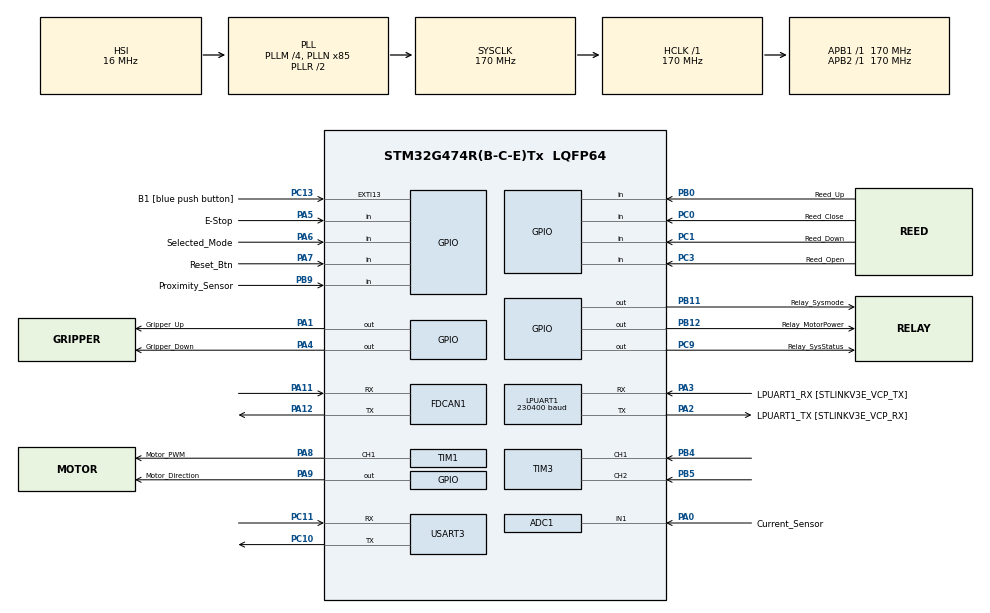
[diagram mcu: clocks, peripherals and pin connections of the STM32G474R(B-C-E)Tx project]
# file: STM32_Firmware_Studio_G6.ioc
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ADC1.Channel-0\#ChannelRegularConversion=ADC_CHANNEL_1
ADC1.ContinuousConvMode=ENABLE
ADC1.DMAContinuousRequests=ENABLE
ADC1.NbrOfConversionFlag=1
ADC1.OffsetNumber-0\#ChannelRegularConversion=ADC_OFFSET_NONE
ADC1.Rank-0\#ChannelRegularConversion=1
ADC1.SamplingTime-0\#ChannelRegularConversion=ADC_SAMPLETIME_2CYCLES_5
ADC1.master=1
Dma.ADC1.0.Direction=DMA_PERIPH_TO_MEMORY
Dma.ADC1.0.EventEnable=DISABLE
Dma.ADC1.0.Instance=DMA1_Channel1
Dma.ADC1.0.MemDataAlignment=DMA_MDATAALIGN_HALFWORD
Dma.ADC1.0.MemInc=DMA_MINC_ENABLE
Dma.ADC1.0.Mode=DMA_CIRCULAR
Dma.ADC1.0.PeriphDataAlignment=DMA_PDATAALIGN_HALFWORD
Dma.ADC1.0.PeriphInc=DMA_PINC_DISABLE
Dma.ADC1.0.Polarity=HAL_DMAMUX_REQ_GEN_RISING
Dma.ADC1.0.Priority=DMA_PRIORITY_LOW
Dma.ADC1.0.RequestNumber=1
Dma.ADC1.0.SignalID=NONE
Dma.ADC1.0.SyncEnable=DISABLE
Dma.ADC1.0.SyncPolarity=HAL_DMAMUX_SYNC_NO_EVENT
Dma.ADC1.0.SyncRequestNumber=1
Dma.ADC1.0.SyncSignalID=NONE
Dma.LPUART1_RX.1.Direction=DMA_PERIPH_TO_MEMORY
Dma.LPUART1_RX.1.EventEnable=DISABLE
Dma.LPUART1_RX.1.Instance=DMA1_Channel2
Dma.LPUART1_RX.1.MemDataAlignment=DMA_MDATAALIGN_BYTE
Dma.LPUART1_RX.1.MemInc=DMA_MINC_ENABLE
Dma.LPUART1_RX.1.Mode=DMA_NORMAL
Dma.LPUART1_RX.1.PeriphDataAlignment=DMA_PDATAALIGN_BYTE
Dma.LPUART1_RX.1.PeriphInc=DMA_PINC_DISABLE
Dma.LPUART1_RX.1.Polarity=HAL_DMAMUX_REQ_GEN_RISING
Dma.LPUART1_RX.1.Priority=DMA_PRIORITY_LOW
Dma.LPUART1_RX.1.RequestNumber=1
Dma.LPUART1_RX.1.SignalID=NONE
Dma.LPUART1_RX.1.SyncEnable=DISABLE
Dma.LPUART1_RX.1.SyncPolarity=HAL_DMAMUX_SYNC_NO_EVENT
Dma.LPUART1_RX.1.SyncRequestNumber=1
Dma.LPUART1_RX.1.SyncSignalID=NONE
Dma.LPUART1_TX.2.Direction=DMA_MEMORY_TO_PERIPH
Dma.LPUART1_TX.2.EventEnable=DISABLE
Dma.LPUART1_TX.2.Instance=DMA1_Channel3
Dma.LPUART1_TX.2.MemDataAlignment=DMA_MDATAALIGN_BYTE
Dma.LPUART1_TX.2.MemInc=DMA_MINC_ENABLE
Dma.LPUART1_TX.2.Mode=DMA_NORMAL
Dma.LPUART1_TX.2.PeriphDataAlignment=DMA_PDATAALIGN_BYTE
Dma.LPUART1_TX.2.PeriphInc=DMA_PINC_DISABLE
Dma.LPUART1_TX.2.Polarity=HAL_DMAMUX_REQ_GEN_RISING
Dma.LPUART1_TX.2.Priority=DMA_PRIORITY_LOW
Dma.LPUART1_TX.2.RequestNumber=1
Dma.LPUART1_TX.2.SignalID=NONE
Dma.LPUART1_TX.2.SyncEnable=DISABLE
Dma.LPUART1_TX.2.SyncPolarity=HAL_DMAMUX_SYNC_NO_EVENT
Dma.LPUART1_TX.2.SyncRequestNumber=1
Dma.LPUART1_TX.2.SyncSignalID=NONE
Dma.Request0=ADC1
Dma.Request1=LPUART1_RX
Dma.Request2=LPUART1_TX
Dma.Request3=USART3_RX
Dma.Request4=USART3_TX
Dma.USART3_RX.3.Direction=DMA_PERIPH_TO_MEMORY
Dma.USART3_RX.3.EventEnable=DISABLE
Dma.USART3_RX.3.Instance=DMA1_Channel4
Dma.USART3_RX.3.MemDataAlignment=DMA_MDATAALIGN_BYTE
Dma.USART3_RX.3.MemInc=DMA_MINC_ENABLE
Dma.USART3_RX.3.Mode=DMA_NORMAL
Dma.USART3_RX.3.PeriphDataAlignment=DMA_PDATAALIGN_BYTE
Dma.USART3_RX.3.PeriphInc=DMA_PINC_DISABLE
Dma.USART3_RX.3.Polarity=HAL_DMAMUX_REQ_GEN_RISING
Dma.USART3_RX.3.Priority=DMA_PRIORITY_LOW
Dma.USART3_RX.3.RequestNumber=1
Dma.USART3_RX.3.SignalID=NONE
Dma.USART3_RX.3.SyncEnable=DISABLE
Dma.USART3_RX.3.SyncPolarity=HAL_DMAMUX_SYNC_NO_EVENT
Dma.USART3_RX.3.SyncRequestNumber=1
Dma.USART3_RX.3.SyncSignalID=NONE
Dma.USART3_TX.4.Direction=DMA_MEMORY_TO_PERIPH
Dma.USART3_TX.4.EventEnable=DISABLE
Dma.USART3_TX.4.Instance=DMA1_Channel5
Dma.USART3_TX.4.MemDataAlignment=DMA_MDATAALIGN_BYTE
Dma.USART3_TX.4.MemInc=DMA_MINC_ENABLE
Dma.USART3_TX.4.Mode=DMA_NORMAL
Dma.USART3_TX.4.PeriphDataAlignment=DMA_PDATAALIGN_BYTE
Dma.USART3_TX.4.PeriphInc=DMA_PINC_DISABLE
Dma.USART3_TX.4.Polarity=HAL_DMAMUX_REQ_GEN_RISING
Dma.USART3_TX.4.Priority=DMA_PRIORITY_LOW
Dma.USART3_TX.4.RequestNumber=1
Dma.USART3_TX.4.SignalID=NONE
Dma.USART3_TX.4.SyncEnable=DISABLE
Dma.USART3_TX.4.SyncPolarity=HAL_DMAMUX_SYNC_NO_EVENT
Dma.USART3_TX.4.SyncRequestNumber=1
Dma.USART3_TX.4.SyncSignalID=NONE
FDCAN1.CalculateBaudRateNominal=3541666
FDCAN1.CalculateTimeBitNominal=282
FDCAN1.CalculateTimeQuantumNominal=94.11764705882354
LPUART1.BaudRate=230400
LPUART1.Parity=UART_PARITY_EVEN
LPUART1.WordLength=UART_WORDLENGTH_9B
Mcu.Family=STM32G4
Mcu.Name=STM32G474R(B-C-E)Tx
Mcu.Package=LQFP64
NVIC.DMA1_Channel1_IRQn=true\:4\:0\:true\:false\:true\:false\:true\:true
NVIC.DMA1_Channel2_IRQn=true\:4\:0\:true\:false\:true\:false\:true\:true
NVIC.DMA1_Channel3_IRQn=true\:4\:0\:true\:false\:true\:false\:true\:true
NVIC.DMA1_Channel4_IRQn=true\:4\:0\:true\:false\:true\:false\:true\:true
NVIC.DMA1_Channel5_IRQn=true\:4\:0\:true\:false\:true\:false\:true\:true
NVIC.EXTI15_10_IRQn=true\:0\:0\:false\:false\:true\:true\:true\:true
NVIC.LPUART1_IRQn=true\:4\:0\:true\:false\:true\:true\:true\:true
NVIC.PriorityGroup=NVIC_PRIORITYGROUP_4
NVIC.TIM6_DAC_IRQn=true\:1\:0\:true\:false\:true\:true\:true\:true
NVIC.USART3_IRQn=true\:3\:0\:true\:false\:true\:true\:true\:true
PA0.GPIO_Label=Current_Sensor
PA0.Mode=IN1-Single-Ended
PA0.Signal=ADC1_IN1
PA1.GPIO_Label=Gripper_Up
PA1.Signal=GPIO_Output
PA11.Mode=FDCAN_Activate
PA11.Signal=FDCAN1_RX
PA12.Mode=FDCAN_Activate
PA12.Signal=FDCAN1_TX
PA13.GPIO_Label=T_SWDIO
PA13.Signal=SYS_JTMS-SWDIO
PA14.GPIO_Label=T_SWCLK
PA14.Signal=SYS_JTCK-SWCLK
PA2.GPIO_Label=LPUART1_TX [STLINKV3E_VCP_RX]
PA2.Mode=Asynchronous
PA2.Signal=LPUART1_TX
PA3.GPIO_Label=LPUART1_RX [STLINKV3E_VCP_TX]
PA3.Mode=Asynchronous
PA3.Signal=LPUART1_RX
PA4.GPIO_Label=Gripper_Down
PA4.Signal=GPIO_Output
PA5.GPIO_Label=E-Stop
PA5.GPIO_PuPd=GPIO_PULLUP
PA5.Signal=GPIO_Input
PA6.GPIO_Label=Selected_Mode
PA6.GPIO_PuPd=GPIO_PULLUP
PA6.Signal=GPIO_Input
PA7.GPIO_Label=Reset_Btn
PA7.GPIO_PuPd=GPIO_PULLUP
PA7.Signal=GPIO_Input
PA8.GPIO_Label=Motor_PWM
PA8.Signal=S_TIM1_CH1
PA9.GPIO_Label=Motor_Direction
PA9.Signal=GPIO_Output
PB0.GPIO_Label=Reed_Up
PB0.GPIO_PuPd=GPIO_PULLDOWN
PB0.Signal=GPIO_Input
PB11.GPIO_Label=Relay_Sysmode
PB11.Signal=GPIO_Output
PB12.GPIO_Label=Relay_MotorPower
PB12.Signal=GPIO_Output
PB3.GPIO_Label=T_SWO
PB3.Signal=SYS_JTDO-SWO
PB4.GPIO_PuPd=GPIO_NOPULL
PB4.Signal=S_TIM3_CH1
PB5.GPIO_PuPd=GPIO_NOPULL
PB5.Signal=S_TIM3_CH2
PB9.GPIO_Label=Proximity_Sensor
PB9.GPIO_PuPd=GPIO_PULLUP
PB9.Signal=GPIO_Input
PC0.GPIO_Label=Reed_Close
PC0.GPIO_PuPd=GPIO_PULLDOWN
PC0.Signal=GPIO_Input
PC1.GPIO_Label=Reed_Down
PC1.GPIO_PuPd=GPIO_PULLDOWN
PC1.Signal=GPIO_Input
PC10.Mode=Asynchronous
PC10.Signal=USART3_TX
PC11.Mode=Asynchronous
PC11.Signal=USART3_RX
PC13.GPIO_Label=B1 [blue push button]
PC13.Signal=GPXTI13
PC14-OSC32_IN.GPIO_Label=RCC_OSC32_IN
PC14-OSC32_IN.Signal=RCC_OSC32_IN
PC15-OSC32_OUT.GPIO_Label=RCC_OSC32_OUT
PC15-OSC32_OUT.Signal=RCC_OSC32_OUT
PC3.GPIO_Label=Reed_Open
PC3.GPIO_PuPd=GPIO_PULLDOWN
PC3.Signal=GPIO_Input
PC9.GPIO_Label=Relay_SysStatus
PC9.Signal=GPIO_Output
PF0-OSC_IN.GPIO_Label=RCC_OSC_IN
PF0-OSC_IN.Signal=RCC_OSC_IN
PF1-OSC_OUT.GPIO_Label=RCC_OSC_OUT
PF1-OSC_OUT.Signal=RCC_OSC_OUT
ProjectManager.HeapSize=0x200
ProjectManager.StackSize=0x400
ProjectManager.TargetToolchain=STM32CubeIDE
RCC.ADC12Freq_Value=170000000
RCC.ADC345Freq_Value=170000000
RCC.AHBFreq_Value=170000000
RCC.APB1Freq_Value=170000000
RCC.APB1TimFreq_Value=170000000
RCC.APB2Freq_Value=170000000
RCC.APB2TimFreq_Value=170000000
RCC.CortexFreq_Value=170000000
RCC.EXTERNAL_CLOCK_VALUE=12288000
RCC.HCLKFreq_Value=170000000
RCC.HSE_VALUE=24000000
RCC.HSI48_VALUE=48000000
RCC.HSI_VALUE=16000000
RCC.LSE_VALUE=32768
RCC.PLLM=RCC_PLLM_DIV4
RCC.PLLN=85
RCC.RTCClockSelection=RCC_RTCCLKSOURCE_LSE
RCC.SYSCLKFreq_VALUE=170000000
RCC.SYSCLKSource=RCC_SYSCLKSOURCE_PLLCLK
RCC.USBFreq_Value=170000000
RCC.VCOOutputFreq_Value=340000000
SH.S_TIM1_CH1.0=TIM1_CH1,PWM Generation1 CH1
SH.S_TIM3_CH1.0=TIM3_CH1,Encoder_Interface
SH.S_TIM3_CH2.0=TIM3_CH2,Encoder_Interface
TIM1.Channel-PWM\ Generation1\ CH1=TIM_CHANNEL_1
TIM1.PeriodNoDither=50
TIM1.Prescaler=169
TIM3.EncoderMode=TIM_ENCODERMODE_TI12
TIM6.PeriodNoDither=999
TIM6.Prescaler=169
USART3.SwapParam=ADVFEATURE_SWAP_ENABLE
USART3.VirtualMode-Asynchronous=VM_ASYNC
VP_SYS_VS_DBSignals.Mode=DisableDeadBatterySignals
VP_TIM6_VS_ClockSourceINT.Mode=Enable_Timer
board=NUCLEO-G474RE

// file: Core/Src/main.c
/* USER CODE BEGIN Header */
/**
  ******************************************************************************
  * @file           : main.c
  * @brief          : Main program body
  ******************************************************************************
  * @attention
  *
  * Copyright (c) 2026 STMicroelectronics.
  * All rights reserved.
  *
  * This software is licensed under terms that can be found in the LICENSE file
  * in the root directory of this software component.
  * If no LICENSE file comes with this software, it is provided AS-IS.
  *
  ******************************************************************************
  */
/* USER CODE END Header */
#include "main.h"

/* USER CODE BEGIN Includes */
#include "app_main.h"
/* USER CODE END Includes */

ADC_HandleTypeDef hadc1;
DMA_HandleTypeDef hdma_adc1;

FDCAN_HandleTypeDef hfdcan1;

UART_HandleTypeDef hlpuart1;
UART_HandleTypeDef huart3;
DMA_HandleTypeDef hdma_lpuart1_rx;
DMA_HandleTypeDef hdma_lpuart1_tx;
DMA_HandleTypeDef hdma_usart3_rx;
DMA_HandleTypeDef hdma_usart3_tx;

TIM_HandleTypeDef htim1;
TIM_HandleTypeDef htim3;
TIM_HandleTypeDef htim6;

void SystemClock_Config(void);
static void MX_GPIO_Init(void);
static void MX_DMA_Init(void);
static void MX_ADC1_Init(void);
static void MX_LPUART1_UART_Init(void);
static void MX_TIM1_Init(void);
static void MX_TIM3_Init(void);
static void MX_TIM6_Init(void);
static void MX_USART3_UART_Init(void);
static void MX_FDCAN1_Init(void);

int main(void)
{

  /* MCU Configuration--------------------------------------------------------*/

  /* Reset of all peripherals, Initializes the Flash interface and the Systick. */
  HAL_Init();

  /* Configure the system clock */
  SystemClock_Config();

  /* Initialize all configured peripherals */

  MX_GPIO_Init();
  MX_DMA_Init();
  MX_ADC1_Init();
  MX_LPUART1_UART_Init();
  MX_TIM1_Init();
  MX_TIM3_Init();
  MX_TIM6_Init();
  MX_USART3_UART_Init();
  MX_FDCAN1_Init();
  /* USER CODE BEGIN 2 */
  App_Init();
  /* USER CODE END 2 */

  /* Infinite loop */
  while (1)
  {

    /* USER CODE BEGIN 3 */

    App_Run();
  }
  /* USER CODE END 3 */
}

void SystemClock_Config(void)
{
  RCC_OscInitTypeDef RCC_OscInitStruct = {0};
  RCC_ClkInitTypeDef RCC_ClkInitStruct = {0};

  /** Configure the main internal regulator output voltage
  */
  HAL_PWREx_ControlVoltageScaling(PWR_REGULATOR_VOLTAGE_SCALE1_BOOST);

  /** Initializes the RCC Oscillators according to the specified parameters
  * in the RCC_OscInitTypeDef structure.
  */
  RCC_OscInitStruct.OscillatorType = RCC_OSCILLATORTYPE_HSI;
  RCC_OscInitStruct.HSIState = RCC_HSI_ON;
  RCC_OscInitStruct.HSICalibrationValue = RCC_HSICALIBRATION_DEFAULT;
  RCC_OscInitStruct.PLL.PLLState = RCC_PLL_ON;
  RCC_OscInitStruct.PLL.PLLSource = RCC_PLLSOURCE_HSI;
  RCC_OscInitStruct.PLL.PLLM = RCC_PLLM_DIV4;
  RCC_OscInitStruct.PLL.PLLN = 85;
  RCC_OscInitStruct.PLL.PLLP = RCC_PLLP_DIV2;
  RCC_OscInitStruct.PLL.PLLQ = RCC_PLLQ_DIV2;
  RCC_OscInitStruct.PLL.PLLR = RCC_PLLR_DIV2;
  if (HAL_RCC_OscConfig(&RCC_OscInitStruct) != HAL_OK)
  {
    Error_Handler();
  }

  /** Initializes the CPU, AHB and APB buses clocks
  */
  RCC_ClkInitStruct.ClockType = RCC_CLOCKTYPE_HCLK|RCC_CLOCKTYPE_SYSCLK
                              |RCC_CLOCKTYPE_PCLK1|RCC_CLOCKTYPE_PCLK2;
  RCC_ClkInitStruct.SYSCLKSource = RCC_SYSCLKSOURCE_PLLCLK;
  RCC_ClkInitStruct.AHBCLKDivider = RCC_SYSCLK_DIV1;
  RCC_ClkInitStruct.APB1CLKDivider = RCC_HCLK_DIV1;
  RCC_ClkInitStruct.APB2CLKDivider = RCC_HCLK_DIV1;

  if (HAL_RCC_ClockConfig(&RCC_ClkInitStruct, FLASH_LATENCY_4) != HAL_OK)
  {
    Error_Handler();
  }
}

static void MX_ADC1_Init(void)
{

  ADC_MultiModeTypeDef multimode = {0};
  ADC_ChannelConfTypeDef sConfig = {0};

  /** Common config
  */
  hadc1.Instance = ADC1;
  hadc1.Init.ClockPrescaler = ADC_CLOCK_SYNC_PCLK_DIV4;
  hadc1.Init.Resolution = ADC_RESOLUTION_12B;
  hadc1.Init.DataAlign = ADC_DATAALIGN_RIGHT;
  hadc1.Init.GainCompensation = 0;
  hadc1.Init.ScanConvMode = ADC_SCAN_DISABLE;
  hadc1.Init.EOCSelection = ADC_EOC_SINGLE_CONV;
  hadc1.Init.LowPowerAutoWait = DISABLE;
  hadc1.Init.ContinuousConvMode = ENABLE;
  hadc1.Init.NbrOfConversion = 1;
  hadc1.Init.DiscontinuousConvMode = DISABLE;
  hadc1.Init.ExternalTrigConv = ADC_SOFTWARE_START;
  hadc1.Init.ExternalTrigConvEdge = ADC_EXTERNALTRIGCONVEDGE_NONE;
  hadc1.Init.DMAContinuousRequests = ENABLE;
  hadc1.Init.Overrun = ADC_OVR_DATA_PRESERVED;
  hadc1.Init.OversamplingMode = DISABLE;
  if (HAL_ADC_Init(&hadc1) != HAL_OK)
  {
    Error_Handler();
  }

  /** Configure the ADC multi-mode
  */
  multimode.Mode = ADC_MODE_INDEPENDENT;
  if (HAL_ADCEx_MultiModeConfigChannel(&hadc1, &multimode) != HAL_OK)
  {
    Error_Handler();
  }

  /** Configure Regular Channel
  */
  sConfig.Channel = ADC_CHANNEL_1;
  sConfig.Rank = ADC_REGULAR_RANK_1;
  sConfig.SamplingTime = ADC_SAMPLETIME_2CYCLES_5;
  sConfig.SingleDiff = ADC_SINGLE_ENDED;
  sConfig.OffsetNumber = ADC_OFFSET_NONE;
  sConfig.Offset = 0;
  if (HAL_ADC_ConfigChannel(&hadc1, &sConfig) != HAL_OK)
  {
    Error_Handler();
  }

}

static void MX_FDCAN1_Init(void)
{

  hfdcan1.Instance = FDCAN1;
  hfdcan1.Init.ClockDivider = FDCAN_CLOCK_DIV1;
  hfdcan1.Init.FrameFormat = FDCAN_FRAME_CLASSIC;
  hfdcan1.Init.Mode = FDCAN_MODE_NORMAL;
  hfdcan1.Init.AutoRetransmission = DISABLE;
  hfdcan1.Init.TransmitPause = DISABLE;
  hfdcan1.Init.ProtocolException = DISABLE;
  hfdcan1.Init.NominalPrescaler = 16;
  hfdcan1.Init.NominalSyncJumpWidth = 1;
  hfdcan1.Init.NominalTimeSeg1 = 1;
  hfdcan1.Init.NominalTimeSeg2 = 1;
  hfdcan1.Init.DataPrescaler = 1;
  hfdcan1.Init.DataSyncJumpWidth = 1;
  hfdcan1.Init.DataTimeSeg1 = 1;
  hfdcan1.Init.DataTimeSeg2 = 1;
  hfdcan1.Init.StdFiltersNbr = 0;
  hfdcan1.Init.ExtFiltersNbr = 0;
  hfdcan1.Init.TxFifoQueueMode = FDCAN_TX_FIFO_OPERATION;
  if (HAL_FDCAN_Init(&hfdcan1) != HAL_OK)
  {
    Error_Handler();
  }

}

static void MX_LPUART1_UART_Init(void)
{

  hlpuart1.Instance = LPUART1;
  hlpuart1.Init.BaudRate = 230400;
  hlpuart1.Init.WordLength = UART_WORDLENGTH_9B;
  hlpuart1.Init.StopBits = UART_STOPBITS_1;
  hlpuart1.Init.Parity = UART_PARITY_EVEN;
  hlpuart1.Init.Mode = UART_MODE_TX_RX;
  hlpuart1.Init.HwFlowCtl = UART_HWCONTROL_NONE;
  hlpuart1.Init.OneBitSampling = UART_ONE_BIT_SAMPLE_DISABLE;
  hlpuart1.Init.ClockPrescaler = UART_PRESCALER_DIV1;
  hlpuart1.AdvancedInit.AdvFeatureInit = UART_ADVFEATURE_NO_INIT;
  if (HAL_UART_Init(&hlpuart1) != HAL_OK)
  {
    Error_Handler();
  }
  if (HAL_UARTEx_SetTxFifoThreshold(&hlpuart1, UART_TXFIFO_THRESHOLD_1_8) != HAL_OK)
  {
    Error_Handler();
  }
  if (HAL_UARTEx_SetRxFifoThreshold(&hlpuart1, UART_RXFIFO_THRESHOLD_1_8) != HAL_OK)
  {
    Error_Handler();
  }
  if (HAL_UARTEx_DisableFifoMode(&hlpuart1) != HAL_OK)
  {
    Error_Handler();
  }

}

static void MX_USART3_UART_Init(void)
{

  huart3.Instance = USART3;
  huart3.Init.BaudRate = 115200;
  huart3.Init.WordLength = UART_WORDLENGTH_8B;
  huart3.Init.StopBits = UART_STOPBITS_1;
  huart3.Init.Parity = UART_PARITY_NONE;
  huart3.Init.Mode = UART_MODE_TX_RX;
  huart3.Init.HwFlowCtl = UART_HWCONTROL_NONE;
  huart3.Init.OverSampling = UART_OVERSAMPLING_16;
  huart3.Init.OneBitSampling = UART_ONE_BIT_SAMPLE_DISABLE;
  huart3.Init.ClockPrescaler = UART_PRESCALER_DIV1;
  huart3.AdvancedInit.AdvFeatureInit = UART_ADVFEATURE_SWAP_INIT;
  huart3.AdvancedInit.Swap = UART_ADVFEATURE_SWAP_ENABLE;
  if (HAL_UART_Init(&huart3) != HAL_OK)
  {
    Error_Handler();
  }
  if (HAL_UARTEx_SetTxFifoThreshold(&huart3, UART_TXFIFO_THRESHOLD_1_8) != HAL_OK)
  {
    Error_Handler();
  }
  if (HAL_UARTEx_SetRxFifoThreshold(&huart3, UART_RXFIFO_THRESHOLD_1_8) != HAL_OK)
  {
    Error_Handler();
  }
  if (HAL_UARTEx_DisableFifoMode(&huart3) != HAL_OK)
  {
    Error_Handler();
  }

}

static void MX_TIM1_Init(void)
{

  TIM_MasterConfigTypeDef sMasterConfig = {0};
  TIM_OC_InitTypeDef sConfigOC = {0};
  TIM_BreakDeadTimeConfigTypeDef sBreakDeadTimeConfig = {0};

  htim1.Instance = TIM1;
  htim1.Init.Prescaler = 169;
  htim1.Init.CounterMode = TIM_COUNTERMODE_UP;
  htim1.Init.Period = 50;
  htim1.Init.ClockDivision = TIM_CLOCKDIVISION_DIV1;
  htim1.Init.RepetitionCounter = 0;
  htim1.Init.AutoReloadPreload = TIM_AUTORELOAD_PRELOAD_DISABLE;
  if (HAL_TIM_PWM_Init(&htim1) != HAL_OK)
  {
    Error_Handler();
  }
  sMasterConfig.MasterOutputTrigger = TIM_TRGO_RESET;
  sMasterConfig.MasterOutputTrigger2 = TIM_TRGO2_RESET;
  sMasterConfig.MasterSlaveMode = TIM_MASTERSLAVEMODE_DISABLE;
  if (HAL_TIMEx_MasterConfigSynchronization(&htim1, &sMasterConfig) != HAL_OK)
  {
    Error_Handler();
  }
  sConfigOC.OCMode = TIM_OCMODE_PWM1;
  sConfigOC.Pulse = 0;
  sConfigOC.OCPolarity = TIM_OCPOLARITY_HIGH;
  sConfigOC.OCNPolarity = TIM_OCNPOLARITY_HIGH;
  sConfigOC.OCFastMode = TIM_OCFAST_DISABLE;
  sConfigOC.OCIdleState = TIM_OCIDLESTATE_RESET;
  sConfigOC.OCNIdleState = TIM_OCNIDLESTATE_RESET;
  if (HAL_TIM_PWM_ConfigChannel(&htim1, &sConfigOC, TIM_CHANNEL_1) != HAL_OK)
  {
    Error_Handler();
  }
  sBreakDeadTimeConfig.OffStateRunMode = TIM_OSSR_DISABLE;
  sBreakDeadTimeConfig.OffStateIDLEMode = TIM_OSSI_DISABLE;
  sBreakDeadTimeConfig.LockLevel = TIM_LOCKLEVEL_OFF;
  sBreakDeadTimeConfig.DeadTime = 0;
  sBreakDeadTimeConfig.BreakState = TIM_BREAK_DISABLE;
  sBreakDeadTimeConfig.BreakPolarity = TIM_BREAKPOLARITY_HIGH;
  sBreakDeadTimeConfig.BreakFilter = 0;
  sBreakDeadTimeConfig.BreakAFMode = TIM_BREAK_AFMODE_INPUT;
  sBreakDeadTimeConfig.Break2State = TIM_BREAK2_DISABLE;
  sBreakDeadTimeConfig.Break2Polarity = TIM_BREAK2POLARITY_HIGH;
  sBreakDeadTimeConfig.Break2Filter = 0;
  sBreakDeadTimeConfig.Break2AFMode = TIM_BREAK_AFMODE_INPUT;
  sBreakDeadTimeConfig.AutomaticOutput = TIM_AUTOMATICOUTPUT_DISABLE;
  if (HAL_TIMEx_ConfigBreakDeadTime(&htim1, &sBreakDeadTimeConfig) != HAL_OK)
  {
    Error_Handler();
  }
  HAL_TIM_MspPostInit(&htim1);

}

static void MX_TIM3_Init(void)
{

  TIM_Encoder_InitTypeDef sConfig = {0};
  TIM_MasterConfigTypeDef sMasterConfig = {0};

  htim3.Instance = TIM3;
  htim3.Init.Prescaler = 0;
  htim3.Init.CounterMode = TIM_COUNTERMODE_UP;
  htim3.Init.Period = 65535;
  htim3.Init.ClockDivision = TIM_CLOCKDIVISION_DIV1;
  htim3.Init.AutoReloadPreload = TIM_AUTORELOAD_PRELOAD_DISABLE;
  sConfig.EncoderMode = TIM_ENCODERMODE_TI12;
  sConfig.IC1Polarity = TIM_ICPOLARITY_RISING;
  sConfig.IC1Selection = TIM_ICSELECTION_DIRECTTI;
  sConfig.IC1Prescaler = TIM_ICPSC_DIV1;
  sConfig.IC1Filter = 0;
  sConfig.IC2Polarity = TIM_ICPOLARITY_RISING;
  sConfig.IC2Selection = TIM_ICSELECTION_DIRECTTI;
  sConfig.IC2Prescaler = TIM_ICPSC_DIV1;
  sConfig.IC2Filter = 0;
  if (HAL_TIM_Encoder_Init(&htim3, &sConfig) != HAL_OK)
  {
    Error_Handler();
  }
  sMasterConfig.MasterOutputTrigger = TIM_TRGO_RESET;
  sMasterConfig.MasterSlaveMode = TIM_MASTERSLAVEMODE_DISABLE;
  if (HAL_TIMEx_MasterConfigSynchronization(&htim3, &sMasterConfig) != HAL_OK)
  {
    Error_Handler();
  }

}

static void MX_TIM6_Init(void)
{

  TIM_MasterConfigTypeDef sMasterConfig = {0};

  htim6.Instance = TIM6;
  htim6.Init.Prescaler = 169;
  htim6.Init.CounterMode = TIM_COUNTERMODE_UP;
  htim6.Init.Period = 999;
  htim6.Init.AutoReloadPreload = TIM_AUTORELOAD_PRELOAD_DISABLE;
  if (HAL_TIM_Base_Init(&htim6) != HAL_OK)
  {
    Error_Handler();
  }
  sMasterConfig.MasterOutputTrigger = TIM_TRGO_RESET;
  sMasterConfig.MasterSlaveMode = TIM_MASTERSLAVEMODE_DISABLE;
  if (HAL_TIMEx_MasterConfigSynchronization(&htim6, &sMasterConfig) != HAL_OK)
  {
    Error_Handler();
  }

}

static void MX_DMA_Init(void)
{

  /* DMA controller clock enable */
  __HAL_RCC_DMAMUX1_CLK_ENABLE();
  __HAL_RCC_DMA1_CLK_ENABLE();

  /* DMA interrupt init */
  /* DMA1_Channel1_IRQn interrupt configuration */
  HAL_NVIC_SetPriority(DMA1_Channel1_IRQn, 4, 0);
  HAL_NVIC_EnableIRQ(DMA1_Channel1_IRQn);
  /* DMA1_Channel2_IRQn interrupt configuration */
  HAL_NVIC_SetPriority(DMA1_Channel2_IRQn, 4, 0);
  HAL_NVIC_EnableIRQ(DMA1_Channel2_IRQn);
  /* DMA1_Channel3_IRQn interrupt configuration */
  HAL_NVIC_SetPriority(DMA1_Channel3_IRQn, 4, 0);
  HAL_NVIC_EnableIRQ(DMA1_Channel3_IRQn);
  /* DMA1_Channel4_IRQn interrupt configuration */
  HAL_NVIC_SetPriority(DMA1_Channel4_IRQn, 4, 0);
  HAL_NVIC_EnableIRQ(DMA1_Channel4_IRQn);
  /* DMA1_Channel5_IRQn interrupt configuration */
  HAL_NVIC_SetPriority(DMA1_Channel5_IRQn, 4, 0);
  HAL_NVIC_EnableIRQ(DMA1_Channel5_IRQn);

}

static void MX_GPIO_Init(void)
{
  GPIO_InitTypeDef GPIO_InitStruct = {0};

  /* GPIO Ports Clock Enable */
  __HAL_RCC_GPIOC_CLK_ENABLE();
  __HAL_RCC_GPIOF_CLK_ENABLE();
  __HAL_RCC_GPIOA_CLK_ENABLE();
  __HAL_RCC_GPIOB_CLK_ENABLE();

  /*Configure GPIO pin Output Level */
  HAL_GPIO_WritePin(GPIOA, Gripper_Up_Pin|Gripper_Down_Pin|Motor_Direction_Pin, GPIO_PIN_RESET);

  /*Configure GPIO pin Output Level */
  HAL_GPIO_WritePin(GPIOB, Relay_Sysmode_Pin|Relay_MotorPower_Pin, GPIO_PIN_RESET);

  /*Configure GPIO pin Output Level */
  HAL_GPIO_WritePin(Relay_SysStatus_GPIO_Port, Relay_SysStatus_Pin, GPIO_PIN_RESET);

  /*Configure GPIO pin : B1_Pin */
  GPIO_InitStruct.Pin = B1_Pin;
  GPIO_InitStruct.Mode = GPIO_MODE_IT_RISING;
  GPIO_InitStruct.Pull = GPIO_NOPULL;
  HAL_GPIO_Init(B1_GPIO_Port, &GPIO_InitStruct);

  /*Configure GPIO pins : Reed_Close_Pin Reed_Down_Pin Reed_Open_Pin */
  GPIO_InitStruct.Pin = Reed_Close_Pin|Reed_Down_Pin|Reed_Open_Pin;
  GPIO_InitStruct.Mode = GPIO_MODE_INPUT;
  GPIO_InitStruct.Pull = GPIO_PULLDOWN;
  HAL_GPIO_Init(GPIOC, &GPIO_InitStruct);

  /*Configure GPIO pins : Gripper_Up_Pin Gripper_Down_Pin Motor_Direction_Pin */
  GPIO_InitStruct.Pin = Gripper_Up_Pin|Gripper_Down_Pin|Motor_Direction_Pin;
  GPIO_InitStruct.Mode = GPIO_MODE_OUTPUT_PP;
  GPIO_InitStruct.Pull = GPIO_NOPULL;
  GPIO_InitStruct.Speed = GPIO_SPEED_FREQ_LOW;
  HAL_GPIO_Init(GPIOA, &GPIO_InitStruct);

  /*Configure GPIO pins : E_Stop_Pin Selected_Mode_Pin Reset_Btn_Pin */
  GPIO_InitStruct.Pin = E_Stop_Pin|Selected_Mode_Pin|Reset_Btn_Pin;
  GPIO_InitStruct.Mode = GPIO_MODE_INPUT;
  GPIO_InitStruct.Pull = GPIO_PULLUP;
  HAL_GPIO_Init(GPIOA, &GPIO_InitStruct);

  /*Configure GPIO pin : Reed_Up_Pin */
  GPIO_InitStruct.Pin = Reed_Up_Pin;
  GPIO_InitStruct.Mode = GPIO_MODE_INPUT;
  GPIO_InitStruct.Pull = GPIO_PULLDOWN;
  HAL_GPIO_Init(Reed_Up_GPIO_Port, &GPIO_InitStruct);

  /*Configure GPIO pins : Relay_Sysmode_Pin Relay_MotorPower_Pin */
  GPIO_InitStruct.Pin = Relay_Sysmode_Pin|Relay_MotorPower_Pin;
  GPIO_InitStruct.Mode = GPIO_MODE_OUTPUT_PP;
  GPIO_InitStruct.Pull = GPIO_NOPULL;
  GPIO_InitStruct.Speed = GPIO_SPEED_FREQ_LOW;
  HAL_GPIO_Init(GPIOB, &GPIO_InitStruct);

  /*Configure GPIO pin : Relay_SysStatus_Pin */
  GPIO_InitStruct.Pin = Relay_SysStatus_Pin;
  GPIO_InitStruct.Mode = GPIO_MODE_OUTPUT_PP;
  GPIO_InitStruct.Pull = GPIO_NOPULL;
  GPIO_InitStruct.Speed = GPIO_SPEED_FREQ_LOW;
  HAL_GPIO_Init(Relay_SysStatus_GPIO_Port, &GPIO_InitStruct);

  /*Configure GPIO pin : Proximity_Sensor_Pin */
  GPIO_InitStruct.Pin = Proximity_Sensor_Pin;
  GPIO_InitStruct.Mode = GPIO_MODE_INPUT;
  GPIO_InitStruct.Pull = GPIO_PULLUP;
  HAL_GPIO_Init(Proximity_Sensor_GPIO_Port, &GPIO_InitStruct);

  /* EXTI interrupt init*/
  HAL_NVIC_SetPriority(EXTI15_10_IRQn, 0, 0);
  HAL_NVIC_EnableIRQ(EXTI15_10_IRQn);

}

void Error_Handler(void)
{
  __disable_irq();
  while (1)
  {
  }
}
